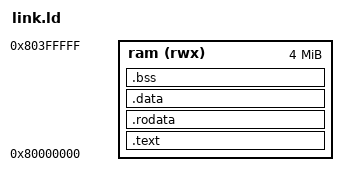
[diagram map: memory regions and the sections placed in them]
OUTPUT_FORMAT("elf32-littleriscv")
OUTPUT_ARCH(riscv)
ENTRY(_start)

MEMORY
{
    ram (rwx) : ORIGIN = 0x80000000, LENGTH = 4M
}

SECTIONS
{
    .text : {
        KEEP(*(.text.start))
        *(.text .text.*)
    } > ram

    .rodata : ALIGN(4) {
        *(.rodata .rodata.*)
        *(.srodata .srodata.*)
    } > ram

    .data : ALIGN(4) {
        *(.data .data.*)
        *(.sdata .sdata.*)
    } > ram

    .bss : ALIGN(4) {
        __bss_start = .;
        *(.bss .bss.*)
        *(.sbss .sbss.*)
        *(COMMON)
        __bss_end = .;
    } > ram

    . = ALIGN(16);
    __stack_bottom = .;
    . = . + 16K;
    __stack_top = .;

    /DISCARD/ : {
        *(.comment)
        *(.eh_frame*)
        *(.note*)
        *(.riscv.attributes)
    }
}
